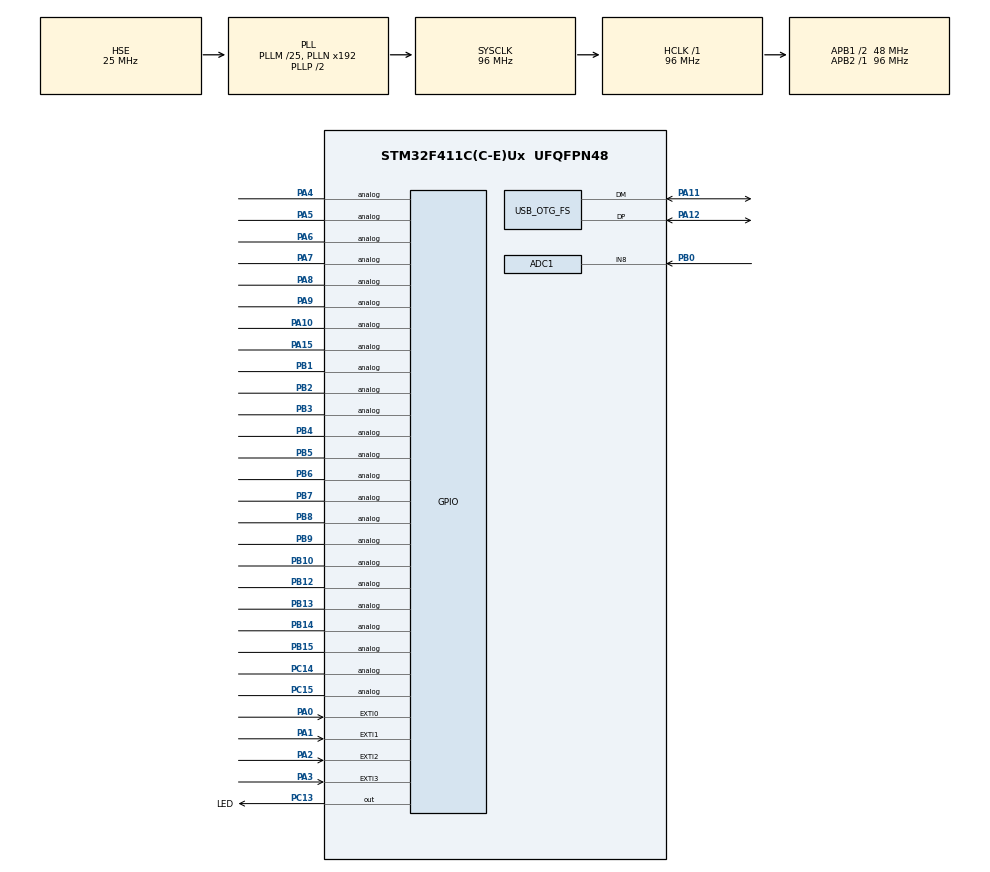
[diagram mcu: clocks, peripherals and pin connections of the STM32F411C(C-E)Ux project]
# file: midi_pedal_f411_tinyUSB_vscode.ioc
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ADC1.Channel-0\#ChannelRegularConversion=ADC_CHANNEL_8
ADC1.ExternalTrigConv=ADC_EXTERNALTRIGCONV_T3_TRGO
ADC1.NbrOfConversionFlag=1
ADC1.Rank-0\#ChannelRegularConversion=1
ADC1.SamplingTime-0\#ChannelRegularConversion=ADC_SAMPLETIME_3CYCLES
ADC1.master=1
Mcu.Family=STM32F4
Mcu.Name=STM32F411C(C-E)Ux
Mcu.Package=UFQFPN48
NVIC.ADC_IRQn=true\:0\:0\:false\:false\:true\:true\:true\:true
NVIC.EXTI0_IRQn=true\:2\:0\:true\:false\:true\:true\:true\:true
NVIC.EXTI1_IRQn=true\:2\:0\:true\:false\:true\:true\:true\:true
NVIC.EXTI2_IRQn=true\:2\:0\:true\:false\:true\:true\:true\:true
NVIC.EXTI3_IRQn=true\:2\:0\:true\:false\:true\:true\:true\:true
NVIC.OTG_FS_IRQn=true\:0\:0\:false\:false\:true\:true\:true\:true
NVIC.PriorityGroup=NVIC_PRIORITYGROUP_4
NVIC.RTC_WKUP_IRQn=true\:0\:0\:false\:false\:true\:true\:true\:true
NVIC.TIM2_IRQn=true\:2\:0\:true\:false\:true\:true\:true\:true
NVIC.TIM3_IRQn=true\:0\:0\:false\:false\:true\:true\:true\:true
PA0-WKUP.GPIO_PuPd=GPIO_PULLUP
PA0-WKUP.Signal=GPXTI0
PA1.GPIO_PuPd=GPIO_PULLUP
PA1.Signal=GPXTI1
PA10.Signal=GPIO_Analog
PA11.Mode=Device_Only
PA11.Signal=USB_OTG_FS_DM
PA12.Mode=Device_Only
PA12.Signal=USB_OTG_FS_DP
PA13.Mode=Serial_Wire
PA13.Signal=SYS_JTMS-SWDIO
PA14.Mode=Serial_Wire
PA14.Signal=SYS_JTCK-SWCLK
PA15.Signal=GPIO_Analog
PA2.GPIO_PuPd=GPIO_PULLUP
PA2.Signal=GPXTI2
PA3.GPIO_PuPd=GPIO_PULLUP
PA3.Signal=GPXTI3
PA4.Signal=GPIO_Analog
PA5.Signal=GPIO_Analog
PA6.Signal=GPIO_Analog
PA7.Signal=GPIO_Analog
PA8.Signal=GPIO_Analog
PA9.Signal=GPIO_Analog
PB0.Signal=ADCx_IN8
PB1.Signal=GPIO_Analog
PB10.Signal=GPIO_Analog
PB12.Signal=GPIO_Analog
PB13.Signal=GPIO_Analog
PB14.Signal=GPIO_Analog
PB15.Signal=GPIO_Analog
PB2.Signal=GPIO_Analog
PB3.Signal=GPIO_Analog
PB4.Signal=GPIO_Analog
PB5.Signal=GPIO_Analog
PB6.Signal=GPIO_Analog
PB7.Signal=GPIO_Analog
PB8.Signal=GPIO_Analog
PB9.Signal=GPIO_Analog
PC13-ANTI_TAMP.GPIO_Label=LED
PC13-ANTI_TAMP.GPIO_PuPd=GPIO_PULLDOWN
PC13-ANTI_TAMP.Signal=GPIO_Output
PC14-OSC32_IN.Signal=GPIO_Analog
PC15-OSC32_OUT.Signal=GPIO_Analog
PH0\ -\ OSC_IN.Mode=HSE-External-Oscillator
PH0\ -\ OSC_IN.Signal=RCC_OSC_IN
PH1\ -\ OSC_OUT.Mode=HSE-External-Oscillator
PH1\ -\ OSC_OUT.Signal=RCC_OSC_OUT
ProjectManager.HeapSize=0x200
ProjectManager.StackSize=0x400
ProjectManager.TargetToolchain=CMake
RCC.48MHZClocksFreq_Value=48000000
RCC.AHBFreq_Value=96000000
RCC.APB1CLKDivider=RCC_HCLK_DIV2
RCC.APB1Freq_Value=48000000
RCC.APB1TimFreq_Value=96000000
RCC.APB2Freq_Value=96000000
RCC.APB2TimFreq_Value=96000000
RCC.CortexFreq_Value=96000000
RCC.HCLKFreq_Value=96000000
RCC.HSE_VALUE=25000000
RCC.HSI_VALUE=16000000
RCC.LSE_VALUE=32768
RCC.PLLM=25
RCC.SYSCLKFreq_VALUE=96000000
RCC.SYSCLKSource=RCC_SYSCLKSOURCE_PLLCLK
RCC.VCOOutputFreq_Value=192000000
RTC.WakeUpClock=RTC_WAKEUPCLOCK_CK_SPRE_16BITS
SH.ADCx_IN8.0=ADC1_IN8,IN8
TIM2.Period=6000000
TIM2.Prescaler=9599
TIM3.Period=8000
TIM3.Prescaler=95
TIM3.TIM_MasterOutputTrigger=TIM_TRGO_UPDATE
TIM5.Prescaler=9599
USB_OTG_FS.VirtualMode=Device_Only
VP_RTC_VS_RTC_Activate.Mode=RTC_Enabled
VP_RTC_VS_RTC_WakeUp_intern.Mode=WakeUp
VP_TIM2_VS_ClockSourceINT.Mode=Internal
VP_TIM3_VS_ClockSourceINT.Mode=Internal
VP_TIM5_VS_ClockSourceINT.Mode=Internal
board=custom

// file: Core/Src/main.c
/* USER CODE BEGIN Header */
/**
  ******************************************************************************
  * @file           : main.c
  * @brief          : Main program body
  ******************************************************************************
  * @attention
  *
  * Copyright (c) 2025 STMicroelectronics.
  * All rights reserved.
  *
  * This software is licensed under terms that can be found in the LICENSE file
  * in the root directory of this software component.
  * If no LICENSE file comes with this software, it is provided AS-IS.
  *
  ******************************************************************************
  */
/* USER CODE END Header */
#include "main.h"
#include "adc.h"
#include "rtc.h"
#include "tim.h"
#include "usb_otg.h"
#include "gpio.h"

/* USER CODE BEGIN Includes */
#include "pedal.hpp"
/* USER CODE END Includes */

void SystemClock_Config(void);

int main(void)
{

  /* MCU Configuration--------------------------------------------------------*/

  /* Reset of all peripherals, Initializes the Flash interface and the Systick. */
  HAL_Init();

  /* Configure the system clock */
  SystemClock_Config();

  /* Initialize all configured peripherals */
  MX_GPIO_Init();
  MX_USB_OTG_FS_PCD_Init();
  MX_TIM2_Init();
  MX_ADC1_Init();
  // MX_RTC_Init();
  MX_TIM3_Init();
  MX_TIM5_Init();
  /* USER CODE BEGIN 2 */
  // bootloader
  #define BOOTLOADER_ADDRESS 0x1FFF0000 // 0x1FFF0000 ? (H7 - 0x1FF09800)
  typedef void (*pFunction)(void);
  pFunction JumpToApplication;
  uint32_t JumpAddress;
   if (HAL_GPIO_ReadPin(GPIOA, GPIO_PIN_0) == GPIO_PIN_RESET) {
    JumpAddress = *(__IO uint32_t*) (BOOTLOADER_ADDRESS + 4);
    JumpToApplication = (pFunction)JumpAddress;
    JumpToApplication();
  }
  // bootloader
  MX_RTC_Init();
  pedal();
  /* USER CODE END 2 */

  /* Infinite loop */
  while (1)
  {

  }
}

void SystemClock_Config(void)
{
  RCC_OscInitTypeDef RCC_OscInitStruct = {0};
  RCC_ClkInitTypeDef RCC_ClkInitStruct = {0};

  /** Configure the main internal regulator output voltage
  */
  __HAL_RCC_PWR_CLK_ENABLE();
  __HAL_PWR_VOLTAGESCALING_CONFIG(PWR_REGULATOR_VOLTAGE_SCALE1);

  /** Initializes the RCC Oscillators according to the specified parameters
  * in the RCC_OscInitTypeDef structure.
  */
  RCC_OscInitStruct.OscillatorType = RCC_OSCILLATORTYPE_LSI|RCC_OSCILLATORTYPE_HSE;
  RCC_OscInitStruct.HSEState = RCC_HSE_ON;
  RCC_OscInitStruct.LSIState = RCC_LSI_ON;
  RCC_OscInitStruct.PLL.PLLState = RCC_PLL_ON;
  RCC_OscInitStruct.PLL.PLLSource = RCC_PLLSOURCE_HSE;
  RCC_OscInitStruct.PLL.PLLM = 25;
  RCC_OscInitStruct.PLL.PLLN = 192;
  RCC_OscInitStruct.PLL.PLLP = RCC_PLLP_DIV2;
  RCC_OscInitStruct.PLL.PLLQ = 4;
  if (HAL_RCC_OscConfig(&RCC_OscInitStruct) != HAL_OK)
  {
    Error_Handler();
  }

  /** Initializes the CPU, AHB and APB buses clocks
  */
  RCC_ClkInitStruct.ClockType = RCC_CLOCKTYPE_HCLK|RCC_CLOCKTYPE_SYSCLK
                              |RCC_CLOCKTYPE_PCLK1|RCC_CLOCKTYPE_PCLK2;
  RCC_ClkInitStruct.SYSCLKSource = RCC_SYSCLKSOURCE_PLLCLK;
  RCC_ClkInitStruct.AHBCLKDivider = RCC_SYSCLK_DIV1;
  RCC_ClkInitStruct.APB1CLKDivider = RCC_HCLK_DIV2;
  RCC_ClkInitStruct.APB2CLKDivider = RCC_HCLK_DIV1;

  if (HAL_RCC_ClockConfig(&RCC_ClkInitStruct, FLASH_LATENCY_3) != HAL_OK)
  {
    Error_Handler();
  }
}

void Error_Handler(void)
{
  __disable_irq();
  while (1)
  {
  }
}
